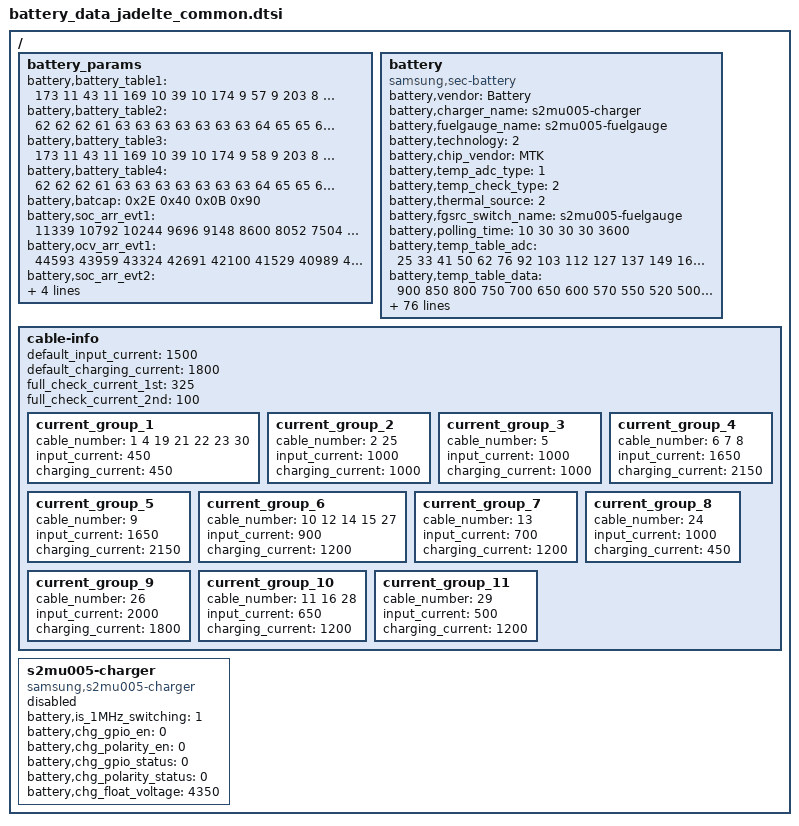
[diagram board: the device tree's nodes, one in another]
/*
 * JADELTE Battery parameters device tree file for board IDs 04 and higher
 *
 * Copyright (C) 2017 Samsung Electronics, Inc.
 *
 * This program is free software; you can redistribute it and/or
 * modify it under the terms of the GNU General Public License
 * as published by the Free Software Foundation; either version 2
 * of the License, or (at your option) any later version.
 *
 * This program is distributed in the hope that it will be useful,
 * but WITHOUT ANY WARRANTY; without even the implied warranty of
 * MERCHANTABILITY or FITNESS FOR A PARTICULAR PURPOSE.  See the
 * GNU General Public License for more details.
 *
 * You should have received a copy of the GNU General Public License
 * along with this program. If not, see <http://www.gnu.org/licenses/>.
 *
 */

/ {
	battery_params {
			battery,battery_table1 = <
					173 11 43 11 169 10 39 10 174 9
					57 9 203 8 101 8 0 8 169 7
					58 7 230 6 175 6 132 6 98 6
					68 6 34 6 245 5 192 5 137 5
					243 4 128 1 18 9 162 8 50 8
					194 7 81 7 225 6 113 6 1 6
					145 5 32 5 176 4 64 4 208 3
					95 3 239 2 127 2 15 2 158 1
					46 1 190 0 78 0 222 15
					>;

			battery,battery_table2 = <
					62 62 62 61 63 63 63 63 63 63
					63 64 65 65 66 67 67 69 71 76
					90 132
					>;

			battery,battery_table3 = <
				173	11	43	11	169	10	39	10	174	9
				58	9	203	8	101	8	0	8	169	7
				58	7	230	6	176	6	133	6	98	6
				68	6	34	6	245	5	192	5	137	5
				243	4	128	1	171	8	64	8	212	7
				105	7	254	6	146	6	39	6	187	5
				80	5	228	4	121	4	13	4	162	3
				55	3	203	2	96	2	244	1	137	1
				30	1	178	0	71	0	220	15
					>;

			battery,battery_table4 = <
				62	62	62	61	63	63	63	63	63	63
				63	64	65	65	66	67	67	69	71	76
				90	132
					>;

			battery,batcap = <0x2E 0x40 0x0B 0x90>; /* [0x0F] [0x0E] [0x11] [0x10] */

			battery,soc_arr_evt1 = <11339 10792 10244 9696 9148 8600 8052 7504 6956 6408 5860 5312 4764 4216 3668 3120 2572 2024 1476 927 380 (-168)>;
			battery,ocv_arr_evt1 = <44593 43959 43324 42691 42100 41529 40989 40491 40001 39574 39034 38625 38357 38147 37977 37833 37666 37446 37186 36919 36186 31873>;

			battery,soc_arr_evt2 = <10834	10310	9787	9262	8738	8213	7689	7164	6640	6115	5591	5066	4542	4018	3493	2969	2444	1920	1395	871	346	(-178)>;
			battery,ocv_arr_evt2 = <44593	43959	43324	42691	42101	41531	40990	40491	40001	39575	39034	38625	38358	38148	37977	37833	37666	37446	37186	36919	36188	31873>;

			battery,FG_Accumulative_rate_evt2 = <0x00 0x8>; /* 0x44 0x45 */
	};

	battery {
		status = "okay";
		compatible = "samsung,sec-battery";

		pinctrl-names = "default";

		battery,vendor = "Battery";
		battery,charger_name = "s2mu005-charger";
		battery,fuelgauge_name = "s2mu005-fuelgauge";
		battery,technology = <2>; /* POWER_SUPPLY_TECHNOLOGY_LION */

		battery,chip_vendor = "MTK";
		battery,temp_adc_type = <1>; /* SEC_BATTERY_ADC_TYPE_AP */

		battery,temp_check_type = <2>; /* SEC_BATTERY_TEMP_CHECK_TEMP */

		battery,thermal_source = <2>; /* SEC_BATTERY_THERMAL_SOURCE_ADC */

		battery,fgsrc_switch_name = "s2mu005-fuelgauge";

		battery,polling_time = <10 30 30 30 3600>;

		battery,temp_table_adc = <
					25 33 41 50 62 76 92 103 112 127
					137 149 168 182 197 220 238 257	301
					365 409	441 475	530 570	633 677	745
					793 864	907 986	1117 1241 1358
					>;

		battery,temp_table_data = <
					900 850 800 750 700 650 600 570
					550 520 500 480 450 430 410 380
					360 340 300 250 220 200 180 150
					130 100 80 50 30 0 (-20) (-50) (-100) (-150) (-200)
					>;

		battery,adc_check_count = <5>;

		battery,cable_check_type = <4>; /* SEC_BATTERY_CABLE_CHECK_PSY */
		battery,cable_source_type = <1>; /* SEC_BATTERY_CABLE_SOURCE_EXTERNAL */
		battery,polling_type = <1>; /* SEC_BATTERY_MONITOR_ALARM */
		battery,monitor_initial_count = <0>;

		battery,battery_check_type = <0>; /* SEC_BATTERY_CHECK_NONE */
		battery,check_count = <0>;
		battery,check_adc_max = <1440>;
		battery,check_adc_min = <0>;

		battery,ovp_uvlo_check_type = <3>; /* SEC_BATTERY_OVP_UVLO_CHGPOLLING */

		battery,temp_check_count = <1>;
		battery,temp_highlimit_threshold_event = <800>;
		battery,temp_highlimit_recovery_event = <750>;
		battery,temp_high_threshold_event = <500>;
		battery,temp_high_recovery_event = <450>;
		battery,temp_low_threshold_event = <(0)>;
		battery,temp_low_recovery_event = <50>;
		battery,temp_highlimit_threshold_normal = <800>;
		battery,temp_highlimit_recovery_normal = <750>;
		battery,temp_high_threshold_normal = <500>;
		battery,temp_high_recovery_normal = <450>;
		battery,temp_low_threshold_normal = <(0)>;
		battery,temp_low_recovery_normal = <50>;
		battery,temp_highlimit_threshold_lpm = <800>;
		battery,temp_highlimit_recovery_lpm = <750>;
		battery,temp_high_threshold_lpm = <500>;
		battery,temp_high_recovery_lpm = <450>;
		battery,temp_low_threshold_lpm = <(0)>;
		battery,temp_low_recovery_lpm = <50>;
		battery,wpc_high_threshold_normal = <450>;
		battery,wpc_high_recovery_normal = <400>;
		battery,wpc_low_threshold_normal = <(0)>;
		battery,wpc_low_recovery_normal = <50>;
		battery,full_check_type = <2>; /* SEC_BATTERY_FULLCHARGED_FG_CURRENT */
		battery,full_check_type_2nd = <2>; /* SEC_BATTERY_FULLCHARGED_FG_CURRENT */
		battery,full_check_count = <1>;
		battery,chg_gpio_full_check = <0>;
		battery,chg_polarity_full_check = <1>;

		/* SEC_BATTERY_FULL_CONDITION_SOC |
		   SEC_BATTERY_FULL_CONDITION_NOTIMEFULL |
		   SEC_BATTERY_FULL_CONDITION_VCELL |
		   SEC_BATTERY_FULL_CONDITION_NOSLEEPINFULL */
		battery,full_condition_type = <15>;
		battery,full_condition_soc = <93>;
		battery,full_condition_vcell = <4250>;

		battery,recharge_check_count = <2>;
		battery,recharge_condition_type = <4>; /* SEC_BATTERY_RECHARGE_CONDITION_VCELL */
		battery,recharge_condition_soc = <98>;
		battery,recharge_condition_vcell = <4300>;

		battery,charging_total_time = <14400>;
		battery,hv_charging_total_time = <10800>;
		battery,normal_charging_total_time = <18000>;
		battery,usb_charging_total_time = <36000>;
		battery,recharging_total_time = <5400>;
		battery,charging_reset_time = <0>;

		battery,chg_float_voltage = <4350>;

		battery,swelling_high_temp_block = <410>;
		battery,swelling_high_temp_recov = <360>;
		battery,swelling_low_temp_block_1st = <150>;
		battery,swelling_low_temp_recov_1st = <200>;
		battery,swelling_low_temp_block_2nd = <50>;
		battery,swelling_low_temp_recov_2nd = <100>;

		battery,swelling_low_temp_current = <750>;	/* 0.3C */
		battery,swelling_low_temp_topoff = <165>;	/* 0.05C */
		battery,swelling_high_temp_current = <1150>;	/* 0.45C */
		battery,swelling_high_temp_topoff = <165>;	/* 0.05C */
		battery,swelling_wc_high_temp_current = <750>;	/* 0.3C */
		battery,swelling_wc_low_temp_current = <750>;	/* 0.3C */

		battery,swelling_drop_float_voltage = <4150>;
		battery,swelling_high_rechg_voltage = <4000>;
		battery,swelling_low_rechg_voltage = <4000>;

		battery,siop_event_check_type = <1>;
		battery,siop_call_cv_current = <330>;
		battery,siop_call_cc_current = <330>;

		battery,siop_input_limit_current = <1200>;
		battery,siop_charging_limit_current = <1000>;

		battery,standard_curr = <1602>; /* TA standard current or AFC current */
		battery,expired_time = <18000>;
		battery,recharging_expired_time = <5400>;

		battery,cisd_max_voltage_thr = <4400>; /* battery ovp detection voltage */
	};

/* sec_battery_cable
 *   0	UNKNOWN,
 *   1	NONE,
 *   2	PREPARE_TA,
 *   3	TA,
 *   4	USB,
 *   5	USB_CDP,
 *   6	9V_TA,
 *   7	9V_ERR,
 *   8	9V_UNKNOWN,
 *   9	12V_TA,
 *  10	WIRELESS,
 *  11	HV_WIRELESS,
 *  12	PMA_WIRELESS,
 *  13	WIRELESS_PACK,
 *  14	WIRELESS_PACK_TA,
 *  15	WIRELESS_STAND,
 *  16	WIRELESS_HV_STAND,
 *  17	QC20,
 *  18	QC30,
 *  19	PDIC,
 *  20	UARTOFF,
 *  21	OTG,
 *  22	LAN_HUB,
 *  23	POWER_SHARING,
 *  24	HMT_CONNECTED,
 *  25	HMT_CHARGE,
 *  26	HV_TA_CHG_LIMIT,
 *  27	WIRELESS_VEHICLE,
 *  28	WIRELESS_HV_VEHICLE,
 *  29	PREPARE_WIRELESS_HV,
 *  30	TIMEOUT,
 *  31	CABLE_MAX,
*/
	cable-info {
		default_input_current = <1500>;
		default_charging_current = <1800>;
		full_check_current_1st = <325>;
		full_check_current_2nd = <100>;

		current_group_1 {
			cable_number = <1 4 19 21 22 23 30>;
			input_current = <450>;
			charging_current = <450>;
		};
		current_group_2 {
			cable_number = <2 25>;
			input_current = <1000>;
			charging_current = <1000>;
		};
		current_group_3 {
			cable_number = <5>;
			input_current = <1000>;
			charging_current = <1000>;
		};
		current_group_4 {
			cable_number = <6 7 8>;
			input_current = <1650>;
			charging_current = <2150>;
		};
		current_group_5 {
			cable_number = <9>;
			input_current = <1650>;
			charging_current = <2150>;
		};
		current_group_6 {
			cable_number = <10 12 14 15 27>;
			input_current = <900>;
			charging_current = <1200>;
		};
		current_group_7 {
			cable_number = <13>;
			input_current = <700>;
			charging_current = <1200>;
		};
		current_group_8 {
			cable_number = <24>;
			input_current = <1000>;
			charging_current = <450>;
		};
		current_group_9 {
			cable_number = <26>;
			input_current = <2000>;
			charging_current = <1800>;
		};
		current_group_10 {
			cable_number = <11 16 28>;
			input_current = <650>;
			charging_current = <1200>;
		};
		current_group_11 {
			cable_number = <29>;
			input_current = <500>;
			charging_current = <1200>;
		};
	};

	s2mu005-charger {
		status = "disable";
		compatible = "samsung,s2mu005-charger";
		battery,is_1MHz_switching = <1>;
		battery,chg_gpio_en = <0>;
		battery,chg_polarity_en = <0>;
		battery,chg_gpio_status = <0>;
		battery,chg_polarity_status = <0>;
		battery,chg_float_voltage = <4350>;
	};
};
